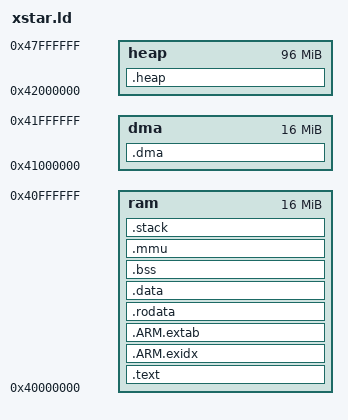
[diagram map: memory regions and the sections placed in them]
OUTPUT_FORMAT("elf32-littlearm", "elf32-bigarm", "elf32-littlearm")
OUTPUT_ARCH(arm)
ENTRY(_start)

STACK_UND_SIZE = 0x40000 * 2;
STACK_ABT_SIZE = 0x40000 * 2;
STACK_IRQ_SIZE = 0x40000 * 2;
STACK_FIQ_SIZE = 0x40000 * 2;
STACK_SRV_SIZE = 0x100000 * 2;

MEMORY
{
	ram  : org = 0x40000000, len = 16M
	dma  : org = 0x41000000, len = 16M
	heap : org = 0x42000000, len = 96M
}

SECTIONS
{
	.text :
	{
		PROVIDE(__image_start = .);
		PROVIDE(__text_start = .);
		*(.text*)
		*(.glue*)
		*(.note.gnu.build-id)
		PROVIDE(__text_end = .);
	} > ram

	.ARM.exidx ALIGN(8) :
	{
		PROVIDE (__exidx_start = .);
		*(.ARM.exidx*)
		PROVIDE (__exidx_end = .);
	} > ram

	.ARM.extab ALIGN(8) :
	{
		PROVIDE (__extab_start = .);
		*(.ARM.extab*)
		PROVIDE (__extab_end = .);
	} > ram

	.rodata ALIGN(8) :
	{
		PROVIDE(__rodata_start = .);
		*(SORT_BY_ALIGNMENT(SORT_BY_NAME(.rodata*)))
		PROVIDE(__rodata_end = .);
	} > ram

	.data ALIGN(8) :
	{
		PROVIDE(__data_start = .);
		*(.data*)
		. = ALIGN(8);
  		PROVIDE(__data_end = .);
		PROVIDE(__image_end = .);
	} > ram

	.bss ALIGN(8) (NOLOAD) :
	{
		PROVIDE(__bss_start = .);
		*(.bss*)
		*(.sbss*)
		*(COMMON)
		. = ALIGN(8);
		PROVIDE(__bss_end = .);
	} > ram

	.mmu ALIGN(0x4000) (NOLOAD) :
	{
		PROVIDE(__mmu_start = .);
		. += 4096;
		PROVIDE(__mmu_end = .);
	} > ram

	.stack ALIGN(8) (NOLOAD) :
	{
		PROVIDE(__stack_start = .);
		PROVIDE(__stack_und_start = .);
		. += STACK_UND_SIZE;
		PROVIDE(__stack_und_end = .);
		. = ALIGN(8);
		PROVIDE(__stack_abt_start = .);
		. += STACK_ABT_SIZE;
		PROVIDE(__stack_abt_end = .);
		. = ALIGN(8);
		PROVIDE(__stack_irq_start = .);
		. += STACK_IRQ_SIZE;
		PROVIDE(__stack_irq_end = .);
		. = ALIGN(8);
		PROVIDE(__stack_fiq_start = .);
		. += STACK_FIQ_SIZE;
		PROVIDE(__stack_fiq_end = .);
		. = ALIGN(8);
		PROVIDE(__stack_srv_start = .);
		. += STACK_SRV_SIZE;
		PROVIDE(__stack_srv_end = .);
		. = ALIGN(8);
		PROVIDE(__stack_end = .);
	} > ram

	.dma ALIGN(8) (NOLOAD) :
	{
		PROVIDE(__dma_start = ORIGIN(dma));
		PROVIDE(__dma_end = ORIGIN(dma) + LENGTH(dma));
	} > dma

	.heap ALIGN(8) (NOLOAD) :
	{
		PROVIDE(__heap_start = ORIGIN(heap));
		PROVIDE(__heap_end = ORIGIN(heap) + LENGTH(heap));
	} > heap

	/DISCARD/ : { *(.dynsym) }
	/DISCARD/ : { *(.dynstr*) }
	/DISCARD/ : { *(.dynamic*) }
	/DISCARD/ : { *(.plt*) }
	/DISCARD/ : { *(.interp*) }
	/DISCARD/ : { *(.gnu*) }
}
